# AVR16EB28 device description
Architecture: AVR8X; Family: AVREB
Registers are 8-bit, read-write, reset 0x0 unless marked. A register's access mark holds for its fields unless they carry their own. Offsets are from the block's base; [hi:lo] are bit positions; {n}, {i} and the like mark numbered series; 'fields as' and 'values as' point back to an identical list.

## EVSYS — Event System
Instances: EVSYS 0x0200
0x00 SWEVENTA — Software Event A
  [7:0] SWEVENTA wo — Software event on channel select
    1=CH0 (Software event on channel 0); 2=CH1 (Software event on channel 1); 4=CH2 (Software event on channel 2); 8=CH3 (Software event on channel 3); 16=CH4 (Software event on channel 4); 32=CH5 (Software event on channel 5); 64=CH6 (Software event on channel 6); 128=CH7 (Software event on channel 7)
{0x10+i} CHANNEL{i} (i=0..5) — Multiplexer Channel {i}
  [7:0] CHANNEL — Channel generator select
    0=OFF; 1=UPDI_SYNCH (UPDI SYNCH character); 6=RTC_OVF (Real Time Counter overflow); 7=RTC_CMP (Real Time Counter compare); 8=RTC_PITEV0 (Periodic Interrupt Timer Event 0); 9=RTC_PITEV1 (Periodic Interrupt Timer Event 1); {v}=CCL_LUT{v-16} (Configurable Custom Logic LUT{v-16}) (v=16..19); 32=AC0_OUT (Analog Comparator 0 out); 33=AC1_OUT (Analog Comparator 1 out); 36=ADC0_RES (ADC 0 Result Ready); 37=ADC0_SAMP (ADC 0 Sample Ready); 38=ADC0_WCMP (ADC 0 Window Compare); 64=PORTA_EV0 (Port A Event 0); 65=PORTA_EV1 (Port A Event 1); 68=PORTC_EV0 (Port C Event 0); 69=PORTC_EV1 (Port C Event 1); 70=PORTD_EV0 (Port D Event 0); 71=PORTD_EV1 (Port D Event 1); 74=PORTF_EV0 (Port F Event 0); 75=PORTF_EV1 (Port F Event 1); 96=USART0_XCK; 104=SPI0_SCK; 128=TCE0_OVF (Timer/Counter E0 overflow); {v}=TCE0_CMP{v-132} (Timer/Counter E0 compare {v-132}) (v=132..135); 160=TCB0_CAPT (Timer/Counter B0 capture); 161=TCB0_OVF (Timer/Counter B0 overflow); 162=TCB1_CAPT (Timer/Counter B1 capture); 163=TCB1_OVF (Timer/Counter B1 overflow); 184=TCF0_OVF (Timer/Counter F0 Overflow); 185=TCF0_CMP0 (Timer/Counter F0 compare 0); 186=TCF0_CMP1 (Timer/Counter F0 compare 1)
{0x20+2i} USERCCLLUT{i}A (i=0..3) — CCL{i} Event A
  [7:0] USER — User channel select
    0=OFF (Off, No Eventsys Channel connected); {v}=CHANNEL{v-1} (Connect user to event channel {v-1}) (v=1..6)
{0x21+2i} USERCCLLUT{i}B (i=0..3) — CCL{i} Event B
  fields as USERCCLLUT0A
0x28 USERADC0START — ADC0 Start
  fields as USERCCLLUT0A
0x29 USEREVSYSEVOUTA — EVOUTA
  fields as USERCCLLUT0A
0x2A USEREVSYSEVOUTC — EVOUTC
  fields as USERCCLLUT0A
0x2B USEREVSYSEVOUTD — EVOUTD
  fields as USERCCLLUT0A
0x2C USEREVSYSEVOUTF — EVOUTF
  fields as USERCCLLUT0A
0x2D USERUSART0IRDA — USART0 IrDA Event
  fields as USERCCLLUT0A
0x2E USERTCE0CNTA — TCE0 Event A
  fields as USERCCLLUT0A
0x2F USERTCE0CNTB — TCE0 Event B
  fields as USERCCLLUT0A
0x30 USERTCB0CAPT — TCB0 Event A
  fields as USERCCLLUT0A
0x31 USERTCB0COUNT — TCB0 Event B
  fields as USERCCLLUT0A
0x32 USERTCB1CAPT — TCB1 Event A
  fields as USERCCLLUT0A
0x33 USERTCB1COUNT — TCB1 Event B
  fields as USERCCLLUT0A
0x34 USERTCF0CNT — TCF0 Clock Event
  fields as USERCCLLUT0A
0x35 USERTCF0ACT — TCF0 Action Event
  fields as USERCCLLUT0A
0x36 USERWEXA — WEX Event A
  fields as USERCCLLUT0A
0x37 USERWEXB — WEX Event B
  fields as USERCCLLUT0A
0x38 USERWEXC — WEX Event C
  fields as USERCCLLUT0A

## FUSE — Fuses
Instances: FUSE 0x1050
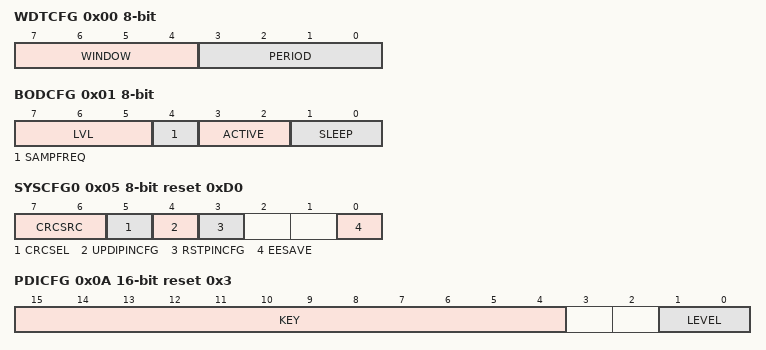
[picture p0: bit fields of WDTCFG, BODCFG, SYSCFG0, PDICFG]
0x00 WDTCFG — Watchdog Configuration
  [7:4] WINDOW — Watchdog Window Timeout Period
    0=OFF (Window mode off); 1=8CLK (8 cycles (8ms)); 2=16CLK (16 cycles (16ms)); 3=32CLK (32 cycles (32ms)); 4=64CLK (64 cycles (64ms)); 5=128CLK (128 cycles (0.128s)); 6=256CLK (256 cycles (0.256s)); 7=512CLK (512 cycles (0.512s)); 8=1KCLK (1K cycles (1.0s)); 9=2KCLK (2K cycles (2.0s)); 10=4KCLK (4K cycles (4.0s)); 11=8KCLK (8K cycles (8.0s))
  [3:0] PERIOD — Watchdog Timeout Period
    0=OFF (Watch-Dog timer Off); 1=8CLK (8 cycles (8ms)); 2=16CLK (16 cycles (16ms)); 3=32CLK (32 cycles (32ms)); 4=64CLK (64 cycles (64ms)); 5=128CLK (128 cycles (0.128s)); 6=256CLK (256 cycles (0.256s)); 7=512CLK (512 cycles (0.512s)); 8=1KCLK (1K cycles (1.0s)); 9=2KCLK (2K cycles (2.0s)); 10=4KCLK (4K cycles (4.0s)); 11=8KCLK (8K cycles (8.0s))
0x01 BODCFG — BOD Configuration
  [7:5] LVL — BOD Level
    0=BODLEVEL0 (BOD Disabled during normal operation); 1=BODLEVEL1 (1.9 V); 2=BODLEVEL2 (2.7 V); 3=BODLEVEL3 (4.5 V)
  [4] SAMPFREQ — BOD Sample Frequency
    0=128HZ (Sampling frequency is 128 Hz); 1=32HZ (Sample frequency is 32 Hz)
  [3:2] ACTIVE — BOD Operation in Active Mode
    0=DISABLE (Disabled); 1=ENABLED (Enabled in continuous mode); 2=SAMPLED (Enabled in sampled mode); 3=ENABLEWAIT (Enabled in continuous mode. Execution halted at wake-up until BOD is running)
  [1:0] SLEEP — BOD Operation in Sleep Mode
    0=DISABLE (Disabled); 1=ENABLE (Enabled in continuous mode); 2=SAMPLE (Enabled in sampled mode)
0x02 OSCCFG — Oscillator Configuration
  [3] OSCHFFRQ — High-frequency Oscillator Frequency
    0=20M (OSCHF running at 20 MHz); 1=16M (OSCHF running at 16 MHz)
0x05 SYSCFG0 reset 0xD0 — System Configuration 0
  [7:6] CRCSRC — CRC Source
    0=FLASH (CRC of full Flash (boot, application code and application data)); 1=BOOT (CRC of boot section); 2=BOOTAPP (CRC of application code and boot sections); 3=NOCRC
  [5] CRCSEL — CRC Select
    0=CRC16 (Enable CRC16); 1=CRC32 (Enable CRC32)
  [4] UPDIPINCFG — UPDI Pin Configuration
    0=GPIO (PF7 Configured as GPIO pin); 1=UPDI (PF7 Configured as UPDI pin)
  [3] RSTPINCFG — Reset Pin Configuration
    0=NONE (No External Reset); 1=RESET (PF6 configured as RESET pin)
  [0] EESAVE — EEPROM Save
    0=DISABLE (EEPROM content is erased during chip erase); 1=ENABLE (EEPROM content is preserved during chip erase)
0x06 SYSCFG1 reset 0x7 — System Configuration 1
  [2:0] SUT — Startup Time
    0=0MS; 1=1MS; 2=2MS; 3=4MS; 4=8MS; 5=16MS; 6=32MS; 7=64MS
0x07 CODESIZE — Code Section Size
0x08 BOOTSIZE — Boot Section Size
0x0A PDICFG 16-bit reset 0x3 — Programming and Debugging Interface Configuration
  [15:4] KEY — NVM Protection Activation Key
    0=NOTACT (Not Active); 0xB45=NVMACT (NVM Protection Active)
  [1:0] LEVEL — Protection Level
    2=NVMACCDIS (NVM Access through UPDI disabled); 3=BASIC (UPDI and UPDI pins working normally)
